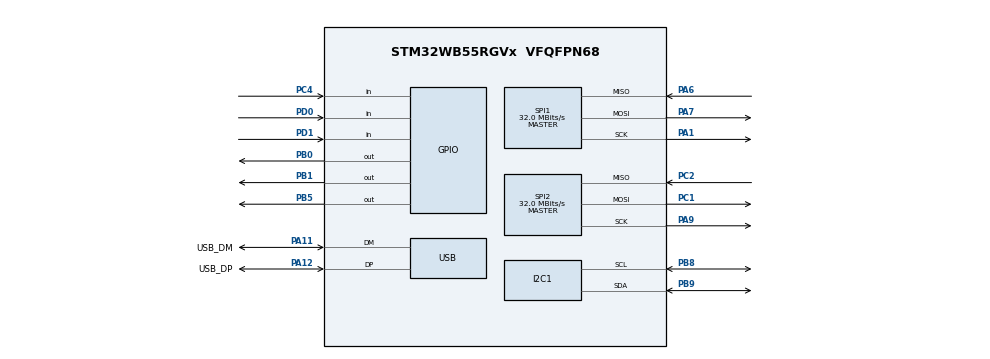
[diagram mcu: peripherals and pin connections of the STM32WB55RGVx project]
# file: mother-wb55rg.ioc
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I2C1.Timing=0x10B17DB5
Mcu.Family=STM32WB
Mcu.Name=STM32WB55RGVx
Mcu.Package=VFQFPN68
NUCLEO-WB55RG.BUTTON=1
NUCLEO-WB55RG.BUTTON2=1
NUCLEO-WB55RG.BUTTON3=1
NUCLEO-WB55RG.LD1=true
NUCLEO-WB55RG.LD2=true
NUCLEO-WB55RG.LD3=true
NUCLEO-WB55RG.VCP=true
NVIC.PriorityGroup=NVIC_PRIORITYGROUP_4
OSC_IN.GPIO_Label=RCC_OSC_IN
OSC_IN.Signal=RCC_OSC_IN
OSC_OUT.GPIO_Label=RCC_OSC_OUT
OSC_OUT.Signal=RCC_OSC_OUT
PA1.Mode=Full_Duplex_Master
PA1.Signal=SPI1_SCK
PA11.GPIO_Label=USB_DM
PA11.Mode=Device
PA11.Signal=USB_DM
PA12.GPIO_Label=USB_DP
PA12.Mode=Device
PA12.Signal=USB_DP
PA13.GPIO_Label=JTMS
PA13.Mode=Trace_Asynchronous_SW
PA13.Signal=SYS_JTMS-SWDIO
PA14.GPIO_Label=JTCK
PA14.Mode=Trace_Asynchronous_SW
PA14.Signal=SYS_JTCK-SWCLK
PA6.Mode=Full_Duplex_Master
PA6.Signal=SPI1_MISO
PA7.Mode=Full_Duplex_Master
PA7.Signal=SPI1_MOSI
PA9.Mode=Full_Duplex_Master
PA9.Signal=SPI2_SCK
PB0.Signal=GPIO_Output
PB1.Signal=GPIO_Output
PB3.GPIO_Label=JTDO
PB3.Mode=Trace_Asynchronous_SW
PB3.Signal=SYS_JTDO-SWO
PB5.Signal=GPIO_Output
PB6.Signal=USART1_TX
PB7.Signal=USART1_RX
PB8.Mode=I2C
PB8.Signal=I2C1_SCL
PB9.Mode=I2C
PB9.Signal=I2C1_SDA
PC1.Mode=Full_Duplex_Master
PC1.Signal=SPI2_MOSI
PC13.GPIO_Label=SYS_WKUP2
PC13.Signal=SYS_WKUP2
PC14-OSC32_IN.GPIO_Label=RCC_OSC32_IN
PC14-OSC32_IN.Signal=RCC_OSC32_IN
PC15-OSC32_OUT.GPIO_Label=RCC_OSC32_OUT
PC15-OSC32_OUT.Signal=RCC_OSC32_OUT
PC2.Mode=Full_Duplex_Master
PC2.Signal=SPI2_MISO
PC4.Signal=GPIO_Input
PD0.Signal=GPIO_Input
PD1.Signal=GPIO_Input
ProjectManager.HeapSize=0x200
ProjectManager.StackSize=0x400
ProjectManager.TargetToolchain=STM32CubeIDE
RCC.ADCFreq_Value=48000000
RCC.AHB2CLKDivider=RCC_SYSCLK_DIV2
RCC.AHBFreq_Value=64000000
RCC.APB1Freq_Value=64000000
RCC.APB1TimFreq_Value=64000000
RCC.APB2Freq_Value=64000000
RCC.APB2TimFreq_Value=64000000
RCC.APB3Freq_Value=16000000
RCC.Cortex2_Div=SYSTICK_CLKSOURCE_HCLK_DIV8
RCC.CortexFreq_Value=64000000
RCC.HCLKFreq_Value=64000000
RCC.HSE_VALUE=32000000
RCC.HSI48_VALUE=48000000
RCC.HSI_VALUE=16000000
RCC.LSE_VALUE=32768
RCC.PLLN=32
RCC.PLLSAI1N=24
RCC.SMPSCLockSelection=RCC_SMPSCLKSOURCE_HSI
RCC.SMPSCLockSelectionVirtual=RCC_SMPSCLKSOURCE_HSI
RCC.SMPSCLockSelectionVirtualVirtual=RCC_SMPSCLKSOURCE_HSI
RCC.SMPSDivider=1
RCC.SYSCLKFreq_VALUE=64000000
RCC.SYSCLKSource=RCC_SYSCLKSOURCE_PLLCLK
RCC.USBFreq_Value=48000000
RCC.VCOOutputFreq_Value=128000000
SPI1.CalculateBaudRate=32.0 MBits/s
SPI1.Direction=SPI_DIRECTION_2LINES
SPI1.Mode=SPI_MODE_MASTER
SPI1.VirtualType=VM_MASTER
SPI2.CalculateBaudRate=32.0 MBits/s
SPI2.Direction=SPI_DIRECTION_2LINES
SPI2.Mode=SPI_MODE_MASTER
SPI2.VirtualType=VM_MASTER
VP_MEMORYMAP_VS_MEMORYMAP.Mode=CurAppReg
VP_NUCLEO-WB55RG_VS_BSP_COMMON.Mode=COMMON
board=NUCLEO-WB55RG

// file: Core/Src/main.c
/* USER CODE BEGIN Header */
/**
  ******************************************************************************
  * @file           : main.c
  * @brief          : Main program body
  ******************************************************************************
  * @attention
  *
  * Copyright (c) 2025 STMicroelectronics.
  * All rights reserved.
  *
  * This software is licensed under terms that can be found in the LICENSE file
  * in the root directory of this software component.
  * If no LICENSE file comes with this software, it is provided AS-IS.
  *
  ******************************************************************************
  */
/* USER CODE END Header */
#include "main.h"

/* USER CODE BEGIN Includes */
#include "tusb.h"
/* USER CODE END Includes */

COM_InitTypeDef BspCOMInit;
I2C_HandleTypeDef hi2c1;

SPI_HandleTypeDef hspi1;
SPI_HandleTypeDef hspi2;

PCD_HandleTypeDef hpcd_USB_FS;

void SystemClock_Config(void);
void PeriphCommonClock_Config(void);
static void MX_GPIO_Init(void);
static void MX_USB_PCD_Init(void);
static void MX_I2C1_Init(void);
static void MX_SPI1_Init(void);
static void MX_SPI2_Init(void);

int main(void)
{

  /* MCU Configuration--------------------------------------------------------*/

  /* Reset of all peripherals, Initializes the Flash interface and the Systick. */
  HAL_Init();

  /* Configure the system clock */
  SystemClock_Config();

  /* Configure the peripherals common clocks */
  PeriphCommonClock_Config();

  /* Initialize all configured peripherals */
  MX_GPIO_Init();
  MX_USB_PCD_Init();
  MX_I2C1_Init();
  MX_SPI1_Init();
  MX_SPI2_Init();
  /* USER CODE BEGIN 2 */

  /* Initialize the TinyUSB stack */
  HAL_PWREx_EnableVddUSB();
  __HAL_RCC_USB_CLK_ENABLE();
  /* 3. Initialize the USB pins and Low-Level hardware */
  /* This is usually handled by the MX_USB_PCD_Init() generated by CubeMX */
  tusb_init();

  /* USER CODE END 2 */

  /* Initialize leds */
  BSP_LED_Init(LED_BLUE);
  BSP_LED_Init(LED_GREEN);
  BSP_LED_Init(LED_RED);

  /* Initialize USER push-button, will be used to trigger an interrupt each time it's pressed.*/
  BSP_PB_Init(BUTTON_SW1, BUTTON_MODE_EXTI);
  BSP_PB_Init(BUTTON_SW2, BUTTON_MODE_EXTI);
  BSP_PB_Init(BUTTON_SW3, BUTTON_MODE_EXTI);

  /* Initialize COM1 port (115200, 8 bits (7-bit data + 1 stop bit), no parity */
  BspCOMInit.BaudRate   = 115200;
  BspCOMInit.WordLength = COM_WORDLENGTH_8B;
  BspCOMInit.StopBits   = COM_STOPBITS_1;
  BspCOMInit.Parity     = COM_PARITY_NONE;
  BspCOMInit.HwFlowCtl  = COM_HWCONTROL_NONE;
  if (BSP_COM_Init(COM1, &BspCOMInit) != BSP_ERROR_NONE)
  {
    Error_Handler();
  }

  /* Infinite loop */
  while (1)
  {

    /* USER CODE BEGIN 3 */
	  /* TinyUSB background task - must be called frequently */
	  printf("Hello world!\n");
	  for(int i = 0 ; i < 50 ; i++) {
		  HAL_Delay(10);
	  	  tud_task();
	  }
  }
  /* USER CODE END 3 */
}

void SystemClock_Config(void)
{
  RCC_OscInitTypeDef RCC_OscInitStruct = {0};
  RCC_ClkInitTypeDef RCC_ClkInitStruct = {0};

  /** Configure the main internal regulator output voltage
  */
  __HAL_PWR_VOLTAGESCALING_CONFIG(PWR_REGULATOR_VOLTAGE_SCALE1);

  /** Initializes the RCC Oscillators according to the specified parameters
  * in the RCC_OscInitTypeDef structure.
  */
  RCC_OscInitStruct.OscillatorType = RCC_OSCILLATORTYPE_HSI|RCC_OSCILLATORTYPE_LSE
                              |RCC_OSCILLATORTYPE_MSI;
  RCC_OscInitStruct.LSEState = RCC_LSE_OFF;
  RCC_OscInitStruct.HSIState = RCC_HSI_ON;
  RCC_OscInitStruct.MSIState = RCC_MSI_ON;
  RCC_OscInitStruct.HSICalibrationValue = RCC_HSICALIBRATION_DEFAULT;
  RCC_OscInitStruct.MSICalibrationValue = RCC_MSICALIBRATION_DEFAULT;
  RCC_OscInitStruct.MSIClockRange = RCC_MSIRANGE_6;
  RCC_OscInitStruct.PLL.PLLState = RCC_PLL_ON;
  RCC_OscInitStruct.PLL.PLLSource = RCC_PLLSOURCE_MSI;
  RCC_OscInitStruct.PLL.PLLM = RCC_PLLM_DIV1;
  RCC_OscInitStruct.PLL.PLLN = 32;
  RCC_OscInitStruct.PLL.PLLP = RCC_PLLP_DIV2;
  RCC_OscInitStruct.PLL.PLLR = RCC_PLLR_DIV2;
  RCC_OscInitStruct.PLL.PLLQ = RCC_PLLQ_DIV2;
  if (HAL_RCC_OscConfig(&RCC_OscInitStruct) != HAL_OK)
  {
    Error_Handler();
  }

  /** Configure the SYSCLKSource, HCLK, PCLK1 and PCLK2 clocks dividers
  */
  RCC_ClkInitStruct.ClockType = RCC_CLOCKTYPE_HCLK4|RCC_CLOCKTYPE_HCLK2
                              |RCC_CLOCKTYPE_HCLK|RCC_CLOCKTYPE_SYSCLK
                              |RCC_CLOCKTYPE_PCLK1|RCC_CLOCKTYPE_PCLK2;
  RCC_ClkInitStruct.SYSCLKSource = RCC_SYSCLKSOURCE_PLLCLK;
  RCC_ClkInitStruct.AHBCLKDivider = RCC_SYSCLK_DIV1;
  RCC_ClkInitStruct.APB1CLKDivider = RCC_HCLK_DIV1;
  RCC_ClkInitStruct.APB2CLKDivider = RCC_HCLK_DIV1;
  RCC_ClkInitStruct.AHBCLK2Divider = RCC_SYSCLK_DIV2;
  RCC_ClkInitStruct.AHBCLK4Divider = RCC_SYSCLK_DIV1;

  if (HAL_RCC_ClockConfig(&RCC_ClkInitStruct, FLASH_LATENCY_3) != HAL_OK)
  {
    Error_Handler();
  }

  /** Enable MSI Auto calibration
  */
  HAL_RCCEx_EnableMSIPLLMode();
}

void PeriphCommonClock_Config(void)
{
  RCC_PeriphCLKInitTypeDef PeriphClkInitStruct = {0};

  /** Initializes the peripherals clock
  */
  PeriphClkInitStruct.PeriphClockSelection = RCC_PERIPHCLK_SMPS;
  PeriphClkInitStruct.SmpsClockSelection = RCC_SMPSCLKSOURCE_HSI;
  PeriphClkInitStruct.SmpsDivSelection = RCC_SMPSCLKDIV_RANGE0;

  if (HAL_RCCEx_PeriphCLKConfig(&PeriphClkInitStruct) != HAL_OK)
  {
    Error_Handler();
  }
}

static void MX_I2C1_Init(void)
{

  hi2c1.Instance = I2C1;
  hi2c1.Init.Timing = 0x10B17DB5;
  hi2c1.Init.OwnAddress1 = 0;
  hi2c1.Init.AddressingMode = I2C_ADDRESSINGMODE_7BIT;
  hi2c1.Init.DualAddressMode = I2C_DUALADDRESS_DISABLE;
  hi2c1.Init.OwnAddress2 = 0;
  hi2c1.Init.OwnAddress2Masks = I2C_OA2_NOMASK;
  hi2c1.Init.GeneralCallMode = I2C_GENERALCALL_DISABLE;
  hi2c1.Init.NoStretchMode = I2C_NOSTRETCH_DISABLE;
  if (HAL_I2C_Init(&hi2c1) != HAL_OK)
  {
    Error_Handler();
  }

  /** Configure Analogue filter
  */
  if (HAL_I2CEx_ConfigAnalogFilter(&hi2c1, I2C_ANALOGFILTER_ENABLE) != HAL_OK)
  {
    Error_Handler();
  }

  /** Configure Digital filter
  */
  if (HAL_I2CEx_ConfigDigitalFilter(&hi2c1, 0) != HAL_OK)
  {
    Error_Handler();
  }

}

static void MX_SPI1_Init(void)
{

  /* SPI1 parameter configuration*/
  hspi1.Instance = SPI1;
  hspi1.Init.Mode = SPI_MODE_MASTER;
  hspi1.Init.Direction = SPI_DIRECTION_2LINES;
  hspi1.Init.DataSize = SPI_DATASIZE_4BIT;
  hspi1.Init.CLKPolarity = SPI_POLARITY_LOW;
  hspi1.Init.CLKPhase = SPI_PHASE_1EDGE;
  hspi1.Init.NSS = SPI_NSS_SOFT;
  hspi1.Init.BaudRatePrescaler = SPI_BAUDRATEPRESCALER_2;
  hspi1.Init.FirstBit = SPI_FIRSTBIT_MSB;
  hspi1.Init.TIMode = SPI_TIMODE_DISABLE;
  hspi1.Init.CRCCalculation = SPI_CRCCALCULATION_DISABLE;
  hspi1.Init.CRCPolynomial = 7;
  hspi1.Init.CRCLength = SPI_CRC_LENGTH_DATASIZE;
  hspi1.Init.NSSPMode = SPI_NSS_PULSE_ENABLE;
  if (HAL_SPI_Init(&hspi1) != HAL_OK)
  {
    Error_Handler();
  }

}

static void MX_SPI2_Init(void)
{

  /* SPI2 parameter configuration*/
  hspi2.Instance = SPI2;
  hspi2.Init.Mode = SPI_MODE_MASTER;
  hspi2.Init.Direction = SPI_DIRECTION_2LINES;
  hspi2.Init.DataSize = SPI_DATASIZE_4BIT;
  hspi2.Init.CLKPolarity = SPI_POLARITY_LOW;
  hspi2.Init.CLKPhase = SPI_PHASE_1EDGE;
  hspi2.Init.NSS = SPI_NSS_SOFT;
  hspi2.Init.BaudRatePrescaler = SPI_BAUDRATEPRESCALER_2;
  hspi2.Init.FirstBit = SPI_FIRSTBIT_MSB;
  hspi2.Init.TIMode = SPI_TIMODE_DISABLE;
  hspi2.Init.CRCCalculation = SPI_CRCCALCULATION_DISABLE;
  hspi2.Init.CRCPolynomial = 7;
  hspi2.Init.CRCLength = SPI_CRC_LENGTH_DATASIZE;
  hspi2.Init.NSSPMode = SPI_NSS_PULSE_ENABLE;
  if (HAL_SPI_Init(&hspi2) != HAL_OK)
  {
    Error_Handler();
  }

}

static void MX_USB_PCD_Init(void)
{

  hpcd_USB_FS.Instance = USB;
  hpcd_USB_FS.Init.dev_endpoints = 8;
  hpcd_USB_FS.Init.speed = PCD_SPEED_FULL;
  hpcd_USB_FS.Init.phy_itface = PCD_PHY_EMBEDDED;
  hpcd_USB_FS.Init.Sof_enable = DISABLE;
  hpcd_USB_FS.Init.low_power_enable = DISABLE;
  hpcd_USB_FS.Init.lpm_enable = DISABLE;
  hpcd_USB_FS.Init.battery_charging_enable = DISABLE;
  if (HAL_PCD_Init(&hpcd_USB_FS) != HAL_OK)
  {
    Error_Handler();
  }

}

static void MX_GPIO_Init(void)
{

  /* GPIO Ports Clock Enable */
  __HAL_RCC_GPIOC_CLK_ENABLE();
  __HAL_RCC_GPIOB_CLK_ENABLE();
  __HAL_RCC_GPIOA_CLK_ENABLE();

}

void Error_Handler(void)
{
  __disable_irq();
  while (1)
  {
  }
}
